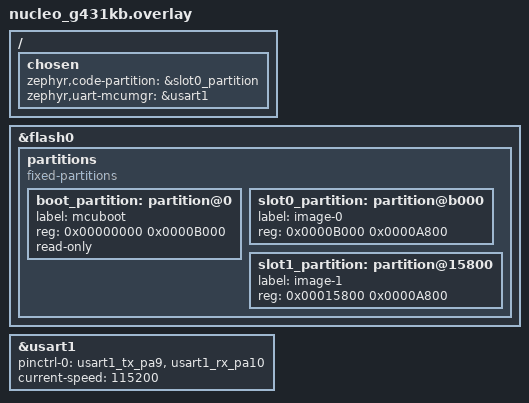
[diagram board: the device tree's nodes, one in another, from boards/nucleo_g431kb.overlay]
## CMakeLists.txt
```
cmake_minimum_required(VERSION 3.20.0)

find_package(Zephyr REQUIRED HINTS $ENV{ZEPHYR_BASE})
project(nucleo_mcuboot)

target_sources(app PRIVATE src/main.c)
```

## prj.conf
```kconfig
CONFIG_BOOTLOADER_MCUBOOT=y
CONFIG_GPIO=y
CONFIG_SERIAL=y
CONFIG_CONSOLE=y
CONFIG_UART_CONSOLE=y
CONFIG_PRINTK=y

CONFIG_FLASH=y
CONFIG_FLASH_PAGE_LAYOUT=y
CONFIG_FLASH_MAP=y
CONFIG_STREAM_FLASH=y
CONFIG_IMG_MANAGER=y
CONFIG_MCUBOOT_IMG_MANAGER=y
CONFIG_NET_BUF=y
CONFIG_ZCBOR=y
CONFIG_BASE64=y
CONFIG_CRC=y

CONFIG_MCUMGR=y
CONFIG_MCUMGR_GRP_IMG=y
CONFIG_MCUMGR_GRP_OS=y
CONFIG_UART_MCUMGR=y
CONFIG_MCUMGR_TRANSPORT_UART=y

CONFIG_MCUBOOT_BOOTLOADER_MODE_SWAP_WITHOUT_SCRATCH=y
CONFIG_MCUBOOT_SIGNATURE_KEY_FILE="/home/halil/myZephyrProjects/nucleo_mcuboot/keys/signing.pem"
```

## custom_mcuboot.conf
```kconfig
# custom_mcuboot.conf
CONFIG_BOOT_SWAP_USING_MOVE=y
#CONFIG_BOOT_UPGRADE_ONLY=y
CONFIG_BOOT_SIGNATURE_TYPE_ECDSA_P256=y
CONFIG_BOOT_SIGNATURE_KEY_FILE="/home/halil/myZephyrProjects/nucleo_mcuboot/keys/signing.pem"
```

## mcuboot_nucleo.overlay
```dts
/ {
        chosen {
                zephyr,code-partition = &boot_partition;
        };
};

&flash0 {
        /delete-node/ partitions;

        partitions {
                compatible = "fixed-partitions";
                #address-cells = <1>;
                #size-cells = <1>;
                ranges;

                boot_partition: partition@0 {
                        label = "mcuboot";
                        reg = <0x00000000 0x0000B000>; /* 44 KB */
                        read-only;
                };

                slot0_partition: partition@b000 {
                        label = "image-0";
                        reg = <0x0000B000 0x0000A800>; /* 42 KB */
                };

                slot1_partition: partition@15800 {
                        label = "image-1";
                        reg = <0x00015800 0x0000A800>; /* 42 KB */
                };
        };
};
```

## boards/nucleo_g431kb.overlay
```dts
/ {
        chosen {
                zephyr,code-partition = &slot0_partition;
                zephyr,uart-mcumgr = &usart1;
        };
};

&flash0 {
        /delete-node/ partitions;

        partitions {
                compatible = "fixed-partitions";
                #address-cells = <1>;
                #size-cells = <1>;
                ranges;

                boot_partition: partition@0 {
                        label = "mcuboot";
                        reg = <0x00000000 0x0000B000>; /* 44 KB */
                        read-only;
                };

                slot0_partition: partition@b000 {
                        label = "image-0";
                        reg = <0x0000B000 0x0000A800>; /* 42 KB */
                };

                slot1_partition: partition@15800 {
                        label = "image-1";
                        reg = <0x00015800 0x0000A800>; /* 42 KB */
                };
        };
};

&usart1 {
        pinctrl-0 = <&usart1_tx_pa9 &usart1_rx_pa10>;
        pinctrl-names = "default";
        current-speed = <115200>;
        status = "okay";
};
```

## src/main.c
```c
#include <zephyr/kernel.h>
#include <zephyr/drivers/gpio.h>
#include <zephyr/sys/printk.h>
#include <zephyr/dfu/mcuboot.h>

#define LED0_NODE DT_ALIAS(led0)

#if !DT_NODE_HAS_STATUS(LED0_NODE, okay)
#error "led0 alias is not defined in devicetree"
#endif

static const struct gpio_dt_spec led = GPIO_DT_SPEC_GET(LED0_NODE, gpios);

static int led_init(void)
{
        if (!gpio_is_ready_dt(&led)) {
                printk("LED device is not ready\n");
                return -1;
        }
        return gpio_pin_configure_dt(&led, GPIO_OUTPUT_INACTIVE);
}

int main(void)
{
        if (led_init() < 0) {
                printk("LED init failed\n");
        }

        printk("Hello from app VERSION 1.0.1\n");

        int confirm_timer = 0;
        while (1) {
                gpio_pin_toggle_dt(&led);
                printk("version 1.0.1\n");
                
                if (confirm_timer < 15) {
                        confirm_timer++;
                        printk("Will confirm image in %d secs (reboot now to test rollback)\n", 15 - confirm_timer);
                        if (confirm_timer == 15) {
                                printk("Confirming image to prevent rollback...\n");
                                boot_write_img_confirmed();
                                printk("Image confirmed! Update is permanent.\n");
                        }
                }
                k_msleep(1000);
        }
        return 0;
}
```
